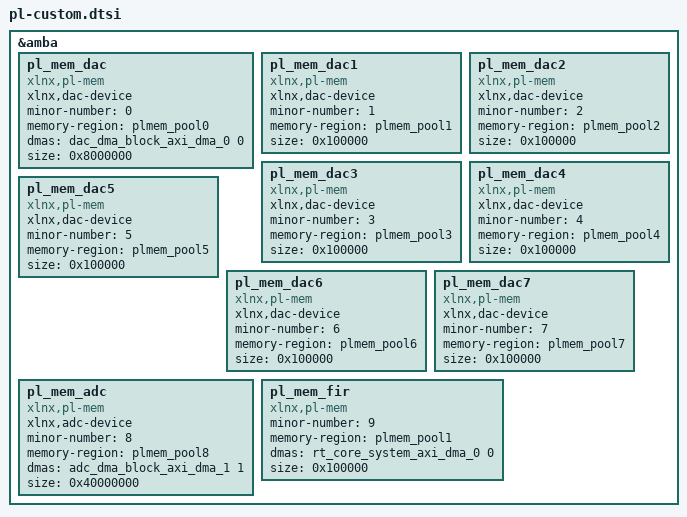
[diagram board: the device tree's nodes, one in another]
/* pl-custom.dtsi
 *
 * NOTE: This file is meant to be INCLUDED into the generated pl.dtsi
 * (so it becomes part of the same pl.dtbo). Do NOT add /dts-v1/ or /plugin/ here.
 */
&amba {
    pl_mem_dac: pl_mem_dac {
        compatible = "xlnx,pl-mem";
        xlnx,dac-device;	
        minor-number = <0>;	
        memory-region = <&plmem_pool0>;
        dmas = <&dac_dma_block_axi_dma_0 0>;
        dma-names = "dac";
        size = <0x8000000>; 
    };
    pl_mem_dac1: pl_mem_dac1 {
        compatible = "xlnx,pl-mem";
        xlnx,dac-device;	
        minor-number = <1>;	
        memory-region = <&plmem_pool1>;
        size = <0x100000>; 
    };
    pl_mem_dac2: pl_mem_dac2 {
        compatible = "xlnx,pl-mem";
        xlnx,dac-device;	
        minor-number = <2>;	
        memory-region = <&plmem_pool2>;
        size = <0x100000>; 
    };
    pl_mem_dac3: pl_mem_dac3 {
        compatible = "xlnx,pl-mem";
        xlnx,dac-device;	
        minor-number = <3>;	
        memory-region = <&plmem_pool3>;
        size = <0x100000>; 
    };
    pl_mem_dac4: pl_mem_dac4 {
        compatible = "xlnx,pl-mem";
        xlnx,dac-device;	
        minor-number = <4>;	
        memory-region = <&plmem_pool4>;
        size = <0x100000>; 
    };
    pl_mem_dac5: pl_mem_dac5 {
        compatible = "xlnx,pl-mem";
        xlnx,dac-device;	
        minor-number = <5>;	
        memory-region = <&plmem_pool5>;
        size = <0x100000>; 
    };
    pl_mem_dac6: pl_mem_dac6 {
        compatible = "xlnx,pl-mem";
        xlnx,dac-device;	
        minor-number = <6>;	
        memory-region = <&plmem_pool6>;
        size = <0x100000>; 
    };
    pl_mem_dac7: pl_mem_dac7 {
        compatible = "xlnx,pl-mem";
        xlnx,dac-device;	
        minor-number = <7>;	
        memory-region = <&plmem_pool7>;
        size = <0x100000>; 
    };
    pl_mem_adc: pl_mem_adc {
        compatible = "xlnx,pl-mem";
        xlnx,adc-device;	
        minor-number = <8>;	
        memory-region = <&plmem_pool8>;
        dmas = <&adc_dma_block_axi_dma_1 1>;
        dma-names = "adc";
        size = <0x40000000>; 
    };
    pl_mem_fir: pl_mem_fir {
        compatible = "xlnx,pl-mem";
        minor-number = <9>;
        memory-region = <&plmem_pool1>;
        dmas = <&rt_core_system_axi_dma_0 0>;   /* MM2S channel */
        dma-names = "fir";
        size = <0x100000>; // (16mb) // change the plmem_pool1 allocation if you change this
        status = "okay";
    };  
};
